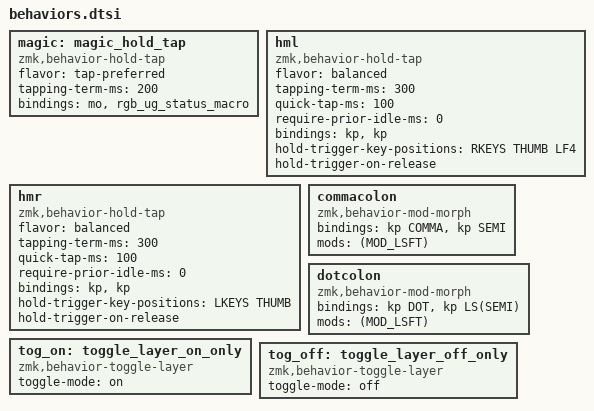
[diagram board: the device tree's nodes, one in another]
magic: magic_hold_tap {
    compatible = "zmk,behavior-hold-tap";
    #binding-cells = <2>;
    flavor = "tap-preferred";
    tapping-term-ms = <200>;
    bindings = <&mo>, <&rgb_ug_status_macro>;
};

hml: hml {
	compatible = "zmk,behavior-hold-tap";
	#binding-cells = <2>;
	flavor = "balanced";
	tapping-term-ms = <300>;
	quick-tap-ms = <100>;
    require-prior-idle-ms = <0>;
    bindings = <&kp>, <&kp>;
    hold-trigger-key-positions = <RKEYS THUMB LF4>;
    hold-trigger-on-release;
};

hmr: hmr {
	compatible = "zmk,behavior-hold-tap";
	#binding-cells = <2>;
	flavor = "balanced";
	tapping-term-ms = <300>;
	quick-tap-ms = <100>;
    require-prior-idle-ms = <0>;
    bindings = <&kp>, <&kp>;
    hold-trigger-key-positions = <LKEYS THUMB>;
    hold-trigger-on-release;
};

commacolon: commacolon {
    compatible = "zmk,behavior-mod-morph";
    #binding-cells = <0>;
    bindings = <&kp COMMA>, <&kp SEMI>;
    mods = <(MOD_LSFT)>;
};
dotcolon: dotcolon {
    compatible = "zmk,behavior-mod-morph";
    #binding-cells = <0>;
    bindings = <&kp DOT>, <&kp LS(SEMI)>;
    mods = <(MOD_LSFT)>;
};

tog_on: toggle_layer_on_only {
    compatible = "zmk,behavior-toggle-layer";
    #binding-cells = <1>;
    toggle-mode = "on";
};
tog_off: toggle_layer_off_only {
    compatible = "zmk,behavior-toggle-layer";
    #binding-cells = <1>;
    toggle-mode = "off";
};
